CM_ "IMPORT _comma.dbc";
CM_ "IMPORT _honda_common.dbc";
CM_ "IMPORT _nidec_common.dbc";
CM_ "IMPORT _steering_sensors_b.dbc";

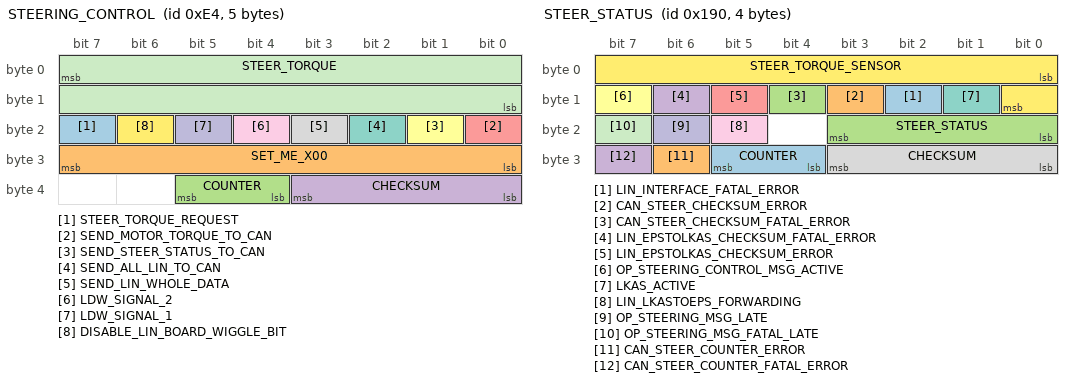
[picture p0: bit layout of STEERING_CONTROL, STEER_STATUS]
BO_ 228 STEERING_CONTROL: 5 ADAS
 SG_ STEER_TORQUE_REQUEST : 23|1@0+ (1,0) [0|1] "" EPS
 SG_ SET_ME_X00 : 31|8@0+ (1,0) [0|0] "" EPS
 SG_ COUNTER : 37|2@0+ (1,0) [0|3] "" EPS
 SG_ CHECKSUM : 35|4@0+ (1,0) [0|3] "" EPS
 SG_ SEND_MOTOR_TORQUE_TO_CAN : 16|1@0+ (1,0) [0|1] "" XXX
 SG_ SEND_STEER_STATUS_TO_CAN : 17|1@0+ (1,0) [0|1] "" XXX
 SG_ SEND_ALL_LIN_TO_CAN : 18|1@0+ (1,0) [0|1] "" XXX
 SG_ SEND_LIN_WHOLE_DATA : 19|1@0+ (1,0) [0|1] "" XXX
 SG_ LDW_SIGNAL_2 : 20|1@0+ (1,0) [0|1] "" XXX
 SG_ LDW_SIGNAL_1 : 21|1@0+ (1,0) [0|1] "" XXX
 SG_ STEER_TORQUE : 7|16@0- (1,0) [-3840|3840] "" EPS
 SG_ DISABLE_LIN_BOARD_WIGGLE_BIT : 22|1@0+ (1,0) [0|1] "" XXX

BO_ 400 STEER_STATUS: 4 EPS
 SG_ LIN_INTERFACE_FATAL_ERROR : 10|1@0+ (1,0) [0|1] "" XXX
 SG_ CAN_STEER_CHECKSUM_ERROR : 11|1@0+ (1,0) [0|1] "" XXX
 SG_ CAN_STEER_CHECKSUM_FATAL_ERROR : 12|1@0+ (1,0) [0|1] "" XXX
 SG_ LIN_EPSTOLKAS_CHECKSUM_FATAL_ERROR : 14|1@0+ (1,0) [0|1] "" XXX
 SG_ LIN_EPSTOLKAS_CHECKSUM_ERROR : 13|1@0+ (1,0) [0|1] "" XXX
 SG_ OP_STEERING_CONTROL_MSG_ACTIVE : 15|1@0+ (1,0) [0|1] "" XXX
 SG_ LKAS_ACTIVE : 9|1@0+ (1,0) [0|1] "" XXX
 SG_ CHECKSUM : 27|4@0+ (1,0) [0|3] "" EON
 SG_ LIN_LKASTOEPS_FORWARDING : 21|1@0+ (1,0) [0|1] "" XXX
 SG_ OP_STEERING_MSG_LATE : 22|1@0+ (1,0) [0|1] "" XXX
 SG_ OP_STEERING_MSG_FATAL_LATE : 23|1@0+ (1,0) [0|1] "" XXX
 SG_ STEER_TORQUE_SENSOR : 0|9@1- (1,0) [-256|256] "" XXX
 SG_ COUNTER : 29|2@0+ (1,0) [0|3] "" EON
 SG_ CAN_STEER_COUNTER_ERROR : 30|1@0+ (1,0) [0|1] "" XXX
 SG_ STEER_STATUS : 16|4@1+ (1,0) [0|15] "" XXX
 SG_ CAN_STEER_COUNTER_FATAL_ERROR : 31|1@0+ (1,0) [0|1] "" XXX

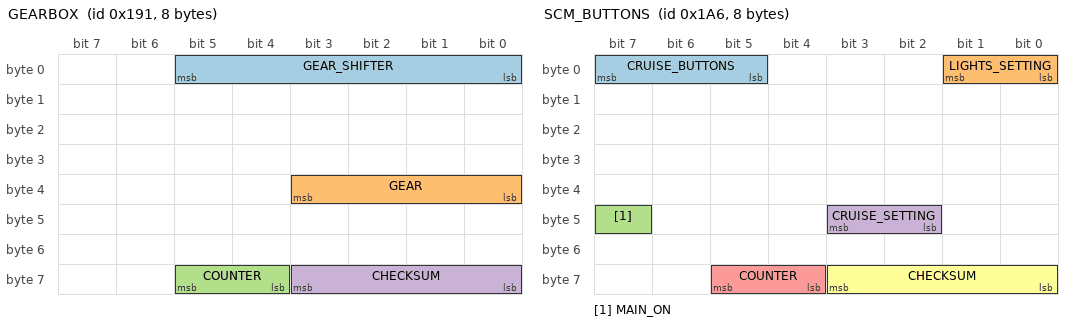
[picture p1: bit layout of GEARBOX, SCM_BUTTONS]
BO_ 401 GEARBOX: 8 PCM
 SG_ GEAR_SHIFTER : 5|6@0+ (1,0) [0|63] "" NEO
 SG_ GEAR : 35|4@0+ (1,0) [0|15] "" NEO
 SG_ COUNTER : 61|2@0+ (1,0) [0|3] "" NEO
 SG_ CHECKSUM : 59|4@0+ (1,0) [0|15] "" NEO

BO_ 422 SCM_BUTTONS: 8 SCM
 SG_ CRUISE_BUTTONS : 7|3@0+ (1,0) [0|7] "" NEO
 SG_ LIGHTS_SETTING : 1|2@0+ (1,0) [0|3] "" NEO
 SG_ MAIN_ON : 47|1@0+ (1,0) [0|1] "" NEO
 SG_ CRUISE_SETTING : 43|2@0+ (1,0) [0|3] "" NEO
 SG_ COUNTER : 61|2@0+ (1,0) [0|3] "" NEO
 SG_ CHECKSUM : 59|4@0+ (1,0) [0|15] "" NEO

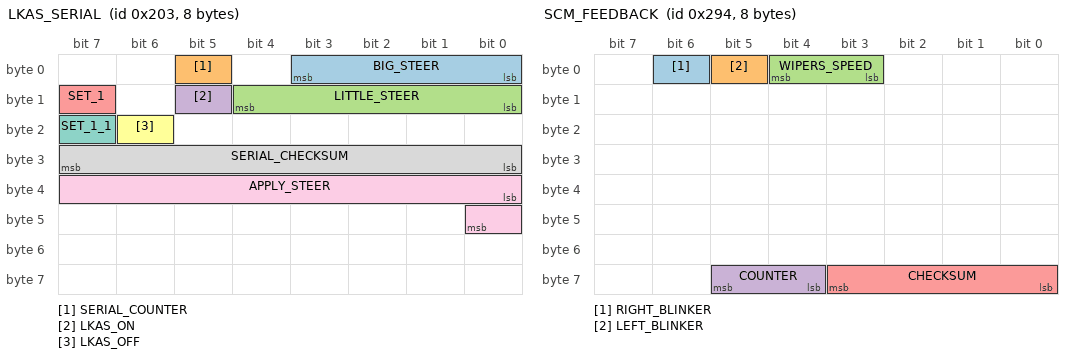
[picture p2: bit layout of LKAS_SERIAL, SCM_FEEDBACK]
BO_ 515 LKAS_SERIAL: 8 XXX
 SG_ BIG_STEER : 3|4@0- (1,0) [0|15] "" XXX
 SG_ SERIAL_COUNTER : 5|1@0+ (1,0) [0|1] "" XXX
 SG_ LITTLE_STEER : 12|5@0- (1,0) [0|31] "" XXX
 SG_ LKAS_ON : 13|1@0+ (1,0) [0|1] "" XXX
 SG_ SET_1 : 15|1@0+ (1,0) [0|1] "" XXX
 SG_ LKAS_OFF : 22|1@0+ (1,0) [0|1] "" XXX
 SG_ SET_1_1 : 23|1@0+ (1,0) [0|1] "" XXX
 SG_ SERIAL_CHECKSUM : 24|8@1+ (1,32) [0|255] "" XXX
 SG_ APPLY_STEER : 32|9@1- (1,0) [-256|255] "" XXX

BO_ 521 LIN_DATA_IN: 8 XXX
 SG_ LITTLE_STEER : 12|5@0+ (1,0) [0|31] "" XXX
 SG_ LKAS_ENABLED_INVERT : 22|1@0+ (1,0) [0|1] "" XXX
 SG_ BIG_DRIVER_TORQUE : 24|4@1+ (1,0) [0|15] "" XXX
 SG_ SMALL_DRIVER_TORQUE : 36|5@0+ (1,0) [0|31] "" XXX
 SG_ SMALL_MOTOR_TORQUE : 54|7@0+ (1,0) [0|127] "" XXX
 SG_ BIG_STEER : 0|4@1+ (1,0) [0|15] "" XXX
 SG_ LKAS_ON_FROM_EPS : 37|1@0+ (1,0) [0|1] "" XXX
 SG_ CAN_CHECKSUM : 56|4@1+ (1,0) [0|15] "" XXX
 SG_ CAN_COUNTER : 61|2@0+ (1,0) [0|3] "" XXX
 SG_ EPS_TO_LKAS_COUNTER_BIT : 29|1@0+ (1,0) [0|1] "" XXX
 SG_ BIG_MOTOR_TORQUE : 45|3@0- (1,0) [0|7] "" XXX
 SG_ UNK_SIGNAL : 4|1@0+ (1,0) [0|1] "" XXX
 SG_ LKAS_ON_FROM_EPS_INVERT : 46|1@0+ (1,0) [0|1] "" XXX
 SG_ LIN_EPS_B1_O6 : 38|1@0+ (1,0) [0|1] "" XXX
 SG_ LIN_EPS_B0_O4 : 28|1@0+ (1,0) [0|1] "" XXX
 SG_ LIN_EPS_B2_O0_2 : 40|3@1+ (1,0) [0|7] "" XXX
 SG_ UNK_LDW_SIGNAL2 : 20|1@0+ (1,0) [0|1] "" XXX
 SG_ LKAS_ENABLED : 13|1@0+ (1,0) [0|1] "" XXX
 SG_ UNK_LDW_SIGNAL1 : 21|1@0+ (1,0) [0|1] "" XXX

BO_ 660 SCM_FEEDBACK: 8 SCM
 SG_ RIGHT_BLINKER : 6|1@0+ (1,0) [0|1] "" NEO
 SG_ LEFT_BLINKER : 5|1@0+ (1,0) [0|1] "" NEO
 SG_ WIPERS_SPEED : 4|2@0+ (1,0) [0|3] "" NEO
 SG_ COUNTER : 61|2@0+ (1,0) [0|3] "" XXX
 SG_ CHECKSUM : 59|4@0+ (1,0) [0|15] "" XXX

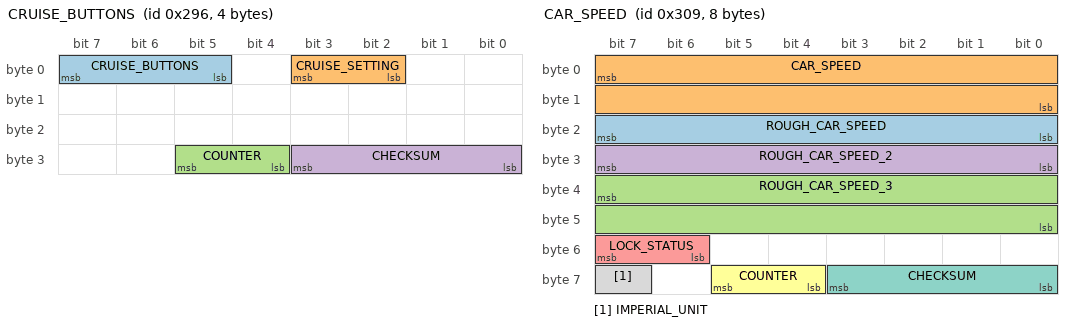
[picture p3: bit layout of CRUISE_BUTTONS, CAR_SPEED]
BO_ 662 CRUISE_BUTTONS: 4 SCM
 SG_ CRUISE_BUTTONS : 7|3@0+ (1,0) [0|7] "" NEO
 SG_ CRUISE_SETTING : 3|2@0+ (1,0) [0|3] "" NEO
 SG_ COUNTER : 29|2@0+ (1,0) [0|3] "" XXX
 SG_ CHECKSUM : 27|4@0+ (1,0) [0|15] "" XXX

BO_ 777 CAR_SPEED: 8 PCM
 SG_ ROUGH_CAR_SPEED : 23|8@0+ (1,0) [0|255] "mph" XXX
 SG_ CAR_SPEED : 7|16@0+ (0.01,0) [0|65535] "kph" XXX
 SG_ ROUGH_CAR_SPEED_3 : 39|16@0+ (0.01,0) [0|65535] "kph" XXX
 SG_ ROUGH_CAR_SPEED_2 : 31|8@0+ (1,0) [0|255] "mph" XXX
 SG_ LOCK_STATUS : 55|2@0+ (1,0) [0|255] "" XXX
 SG_ COUNTER : 61|2@0+ (1,0) [0|3] "" XXX
 SG_ CHECKSUM : 59|4@0+ (1,0) [0|15] "" XXX
 SG_ IMPERIAL_UNIT : 63|1@0+ (1,0) [0|1] "" XXX

 BO_ 780 ACC_HUD: 8 ADAS
 SG_ PCM_SPEED : 7|16@0+ (0.01,0) [0|250] "kph" BDY
 SG_ PCM_GAS : 23|8@0+ (1,0) [0|127] "" BDY
 SG_ CRUISE_SPEED : 31|8@0+ (1,0) [0|255] "kph" BDY
 SG_ DTC_MODE : 39|1@0+ (1,0) [0|1] "" BDY
 SG_ BOH : 38|1@0+ (1,0) [0|1] "" BDY
 SG_ ACC_PROBLEM : 37|1@0+ (1,0) [0|1] "" BDY
 SG_ FCM_OFF : 35|1@0+ (1,0) [0|1] "" BDY
 SG_ FCM_OFF_2 : 36|1@0+ (1,0) [0|1] "" BDY
 SG_ FCM_PROBLEM : 34|1@0+ (1,0) [0|1] "" BDY
 SG_ RADAR_OBSTRUCTED : 33|1@0+ (1,0) [0|1] "" BDY
 SG_ ENABLE_MINI_CAR : 32|1@0+ (1,0) [0|1] "" BDY
 SG_ HUD_DISTANCE : 47|2@0+ (1,0) [0|3] "" BDY
 SG_ HUD_LEAD : 45|2@0+ (1,0) [0|3] "" BDY
 SG_ BOH_3 : 43|1@0+ (1,0) [0|3] "" BDY
 SG_ BOH_4 : 42|1@0+ (1,0) [0|3] "" BDY
 SG_ BOH_5 : 41|1@0+ (1,0) [0|3] "" BDY
 SG_ CRUISE_CONTROL_LABEL : 40|1@0+ (1,0) [0|3] "" BDY
 SG_ SET_ME_X01_2 : 55|1@0+ (1,0) [0|1] "" BDY
 SG_ IMPERIAL_UNIT : 54|1@0+ (1,0) [0|1] "" BDY
 SG_ ACC_ON : 52|1@0+ (1,0) [0|1] "" BDY
 SG_ CHIME : 51|3@0+ (1,0) [0|1] "" BDY
 SG_ SET_ME_X01 : 48|1@0+ (1,0) [0|1] "" BDY
 SG_ ICONS : 63|2@0+ (1,0) [0|1] "" BDY
 SG_ COUNTER : 61|2@0+ (1,0) [0|3] "" BDY
 SG_ CHECKSUM : 59|4@0+ (1,0) [0|3] "" BDY

BO_ 927 ACC_HUD_2: 8 ADAS
 SG_ ZEROS_BOH : 7|17@0+ (1,0) [0|127] "" BDY
 SG_ APPLY_BRAKES_FOR_CANC : 23|1@0+ (1,0) [0|15] "" BDY
 SG_ ZEROS_BOH2 : 31|8@0+ (1,0) [0|127] "" BDY
 SG_ RESUME_INSTRUCTION : 21|1@0+ (1,0) [0|15] "" BDY
 SG_ ACC_ALERTS : 20|5@0+ (1,0) [0|15] "" BDY
 SG_ LEAD_SPEED : 39|9@0+ (1,0) [0|127] "" BDY
 SG_ LEAD_STATE : 46|3@0+ (1,0) [0|127] "" BDY
 SG_ LEAD_DISTANCE : 43|5@0+ (1,0) [0|31] "" BDY
 SG_ ZEROS_BOH3 : 54|7@0+ (1,0) [0|127] "" BDY
 SG_ COUNTER : 61|2@0+ (1,0) [0|3] "" XXX
 SG_ CHECKSUM : 59|4@0+ (1,0) [0|15] "" XXX

VAL_ 400 STEER_STATUS 6 "tmp_fault" 5 "fault_1" 4 "no_torque_alert_2" 3 "low_speed_lockout" 2 "no_torque_alert_1" 0 "normal" ;
VAL_ 401 GEAR_SHIFTER 32 "L" 16 "S" 8 "D" 4 "N" 2 "R" 1 "P" ;
CM_ "CHFFR_METRIC 342 STEER_ANGLE STEER_ANGLE 0.36 180; CHFFR_METRIC 380 ENGINE_RPM ENGINE_RPM 1 0; CHFFR_METRIC 804 ENGINE_TEMPERATURE ENGINE_TEMPERATURE 1 0";
